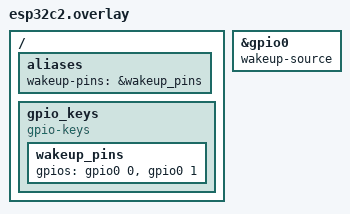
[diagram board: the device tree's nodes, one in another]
/*
 * Copyright (c) 2025-2026 Espressif Systems (Shanghai) Co., Ltd.
 *
 * SPDX-License-Identifier: Apache-2.0
 */

/ {
	aliases {
		/* On ESP32-C2, only GPIO0~5 can be used
		 * as wake-up sources
		 */
		wakeup-pins = &wakeup_pins;
	};

	gpio_keys {
		compatible = "gpio-keys";

		wakeup_pins: wakeup_pins {
			gpios = <&gpio0 0 (GPIO_PULL_DOWN | GPIO_ACTIVE_HIGH | GPIO_INT_WAKEUP)>,
				<&gpio0 1 (GPIO_PULL_DOWN | GPIO_ACTIVE_HIGH | GPIO_INT_WAKEUP)>;
		};
	};
};

&gpio0 {
	/* Configure device as wakeup source */
	wakeup-source;
};
